# NUC400_v1 register map
File version: 1.0
Registers are 32-bit, read-write, reset 0x0 unless marked. A register's access mark holds for its fields unless they carry their own. Offsets are from the block's base; [hi:lo] are bit positions; {n}, {i} and the like mark numbered series.

## NMI — NMI Register Map
Base 0x40000300
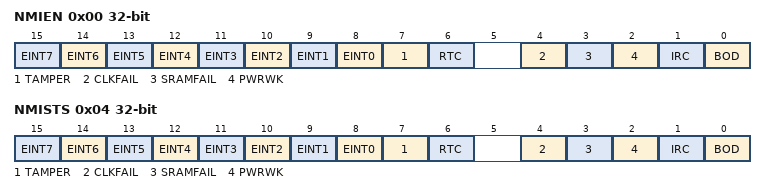
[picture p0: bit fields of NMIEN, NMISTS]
0x00 NMIEN — NMI Source Interrupt Enable Control Register
  [n+8] EINT{n} (n=0..7) — External Interrupt {n} NMI Source Enable
    0=External interrupt {n} NMI source Disabled; 1=External interrupt {n} NMI source Enabled
  [7] TAMPER — TAMPER_INT NMI Source Enable
    0=Backup register tamper detected interrupt.NMI source Disabled; 1=Backup register tamper detected interrupt.NMI source Enabled
  [6] RTC — RTC NMI Source Enable
    0=RTC NMI source Disabled; 1=RTC NMI source Enabled
  [4] CLKFAIL — Clock Fail Detected NMI Source Enable
    0=Clock fail detected interrupt NMI source Disabled; 1=Clock fail detected interrupt NMI source Enabled
  [3] SRAMFAIL — SRAM ParityCheck Error NMI Source Enable
    0=SRAM parity check error NMI source Disabled; 1=SRAM parity check error NMI source Enabled
  [2] PWRWK — Power-down Mode Wake-up NMI Source Enable
    0=Power-down mode wake-up NMI source Disabled; 1=Power-down mode wake-up NMI source Enabled
  [1] IRC — IRC TRIM NMI Source Enable
    0=IRC TRIM NMI source Disabled; 1=IRC TRIM NMI source Enabled
  [0] BOD — BOD NMI Source Enable
    0=BOD NMI source Disabled; 1=BOD NMI source Enabled
0x04 NMISTS ro — NMI Source Interrupt Status Register
  [n+8] EINT{n} (n=0..7) — External Interrupt {n} Interrupt Flag (Read Only)
    0=External Interrupt {n} interrupt is deasserted; 1=External Interrupt {n} interrupt is asserted
  [7] TAMPER — TAMPER_INT Interrupt Flag (Read Only)
    0=Backup register tamper detected interrupt is deasserted; 1=Backup register tamper detected interrupt is asserted
  [6] RTC — RTC Interrupt Flag (Read Only)
    0=RTC interrupt is deasserted; 1=RTC interrupt is asserted
  [4] CLKFAIL — Clock Fail Detected Interrupt Flag (Read Only)
    0=Clock fail detected interrupt is deasserted; 1=Clock fail detected interrupt is asserted
  [3] SRAMFAIL — SRAM ParityCheck Error Interrupt Flag (Read Only)
    0=SRAM parity check error interrupt is deasserted; 1=SRAM parity check error interrupt is asserted
  [2] PWRWK — Power-down Mode Wake-up Interrupt Flag (Read Only)
    0=Power-down mode wake-up interrupt is deasserted; 1=Power-down mode wake-up interrupt is asserted
  [1] IRC — IRC TRIM Interrupt Flag (Read Only)
    0=HIRC TRIM interrupt is deasserted; 1=HIRC TRIM interrupt is asserted
  [0] BOD — BOD Interrupt Flag (Read Only)
    0=BOD interrupt is deasserted; 1=BOD interrupt is asserted

## WWDT — WWDT Register Map
Base 0x40040100
0x00 WWDT_RLDCNT wo — Window Watchdog Timer Reload Counter Register
  [31:0] RLDCNT — WWDT Reload Counter Bit. Writing 0x00005AA5 to this register will reload the Window Watchdog Timer counter value to 0x3F. Note: Software can only write RLDCNT to reload WWDT counter value when current WWDT counter value between 0 and CMPDAT. If software writes RLDCNT when current WWDT counter value is larger than CMPDAT, WWDT reset signal will generate immediately.
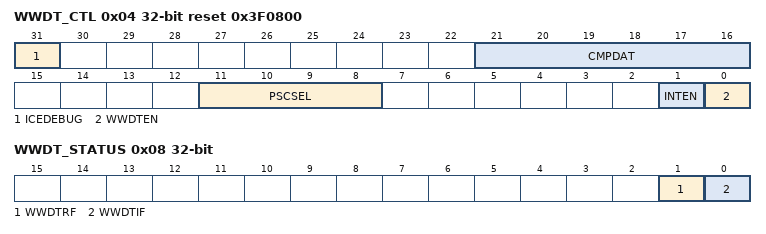
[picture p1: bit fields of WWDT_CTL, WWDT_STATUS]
0x04 WWDT_CTL reset 0x3F0800 — Window Watchdog Timer Control Register
  [31] ICEDEBUG — ICE Debug Mode Acknowledge Disable Bit. WWDT down counter will keep going no matter CPU is held by ICE or not.
    0=ICE debug mode acknowledgement effects WWDT counting; 1=ICE debug mode acknowledgement Disabled
  [21:16] CMPDAT — WWDT Window Compare Bits. Set this register to adjust the valid reload window. Note: Software can only write RLDCNT to reload WWDT counter value when current WWDT counter value between 0 and CMPDAT. If Software writes RLDCNT when current WWDT counter value larger than CMPDAT, WWDT reset signal will generate immediately.
  [11:8] PSCSEL — WWDT Counter Prescale Period Selection
    0=Pre-scale is 1; Max time-out period is 1 * 64 * TWWDT; 1=Pre-scale is 2; Max time-out period is 2 * 64 * TWWDT; 2=Pre-scale is 4; Max time-out period is 4 * 64 * TWWDT; 3=Pre-scale is 8; Max time-out period is 8 * 64 * TWWDT; 4=Pre-scale is 16; Max time-out period is 16 * 64 * TWWDT; 5=Pre-scale is 32; Max time-out period is 32 * 64 * TWWDT; 6=Pre-scale is 64; Max time-out period is 64 * 64 * TWWDT; 7=Pre-scale is 128; Max time-out period is 128 * 64 * TWWDT; 8=Pre-scale is 192; Max time-out period is 192 * 64 * TWWDT; 9=Pre-scale is 256; Max time-out period is 256 * 64 * TWWDT; 10=Pre-scale is 384; Max time-out period is 384 * 64 * TWWDT; 11=Pre-scale is 512; Max time-out period is 512 * 64 * TWWDT; 12=Pre-scale is 768; Max time-out period is 768 * 64 * TWWDT; 13=Pre-scale is 1024; Max time-out period is 1024 * 64 * TWWDT; 14=Pre-scale is 1536; Max time-out period is 1536 * 64 * TWWDT; 15=Pre-scale is 2048; Max time-out period is 2048 * 64 * TWWDT
  [1] INTEN — WWDT Interrupt Enable Bit. If this bit is enabled, the WWDT counter compare match interrupt signal is generated and inform to CPU.
    0=WWDT counter compare match interrupt Disabled; 1=WWDT counter compare match interrupt Enabled
  [0] WWDTEN — WWDT Enable Bit. Set this bit to enable Window Watchdog Timer counter counting.
    0=Window Watchdog Timer counter is stopped; 1=Window Watchdog Timer counter is starting counting
0x08 WWDT_STATUS — Window Watchdog Timer Status Register
  [1] WWDTRF — WWDT Timer-Out Reset Flag. This bit indicates the system has been reset by WWDT time-out reset or not. Note: This bit is cleared by writing 1 to it.
    0=WWDT time-out reset did not occur; 1=WWDT time-out reset occurred
  [0] WWDTIF — WWDT Compare Match Interrupt Flag. This bit indicates the interrupt flag status of WWDT while WWDT counter value matches CMPDAT value. Note: This bit is cleared by writing 1 to it.
    0=No effect; 1=WWDT counter value matches CMPDAT value
0x0C WWDT_CNT ro reset 0x3F — Window Watchdog Timer Counter Value Register
  [5:0] CNTDAT — WWDT Counter Value. This register reflects the current WWDT counter value and is read only.
